VERSION "1.0"

NS_ :

BS_:

BU_: EngineECU ADAS_ECU BodyControl BatteryECU CrashSensor ACU LoadMonitor FaultInjector

BO_ 1 CRASH_Detected: 1 CrashSensor
 SG_ CrashFlag : 0|1@1+ (1,0) [0|1] "" Vector__XXX

BO_ 2 AIRBAG_Deploy: 1 ACU
 SG_ DeployCmd : 0|1@1+ (1,0) [0|1] "" Vector__XXX

BO_ 80 ACC_Data: 4 CrashSensor
 SG_ LongAccel : 0|16@1- (0.01,0) [-50|50] "m/s2" Vector__XXX
 SG_ LatAccel : 16|16@1- (0.01,0) [-50|50] "m/s2" Vector__XXX

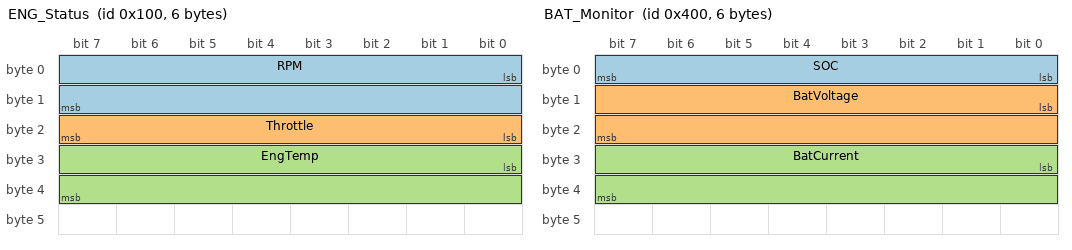
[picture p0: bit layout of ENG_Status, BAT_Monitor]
BO_ 256 ENG_Status: 6 EngineECU
 SG_ RPM : 0|16@1+ (0.25,0) [0|8000] "rpm" Vector__XXX
 SG_ Throttle : 16|8@1+ (0.5,0) [0|100] "%" Vector__XXX
 SG_ EngTemp : 24|16@1+ (0.1,-40) [-40|250] "degC" Vector__XXX

BO_ 257 ENG_Control: 3 EngineECU
 SG_ FuelInjPW : 0|16@1+ (0.01,0) [0|20] "ms" Vector__XXX
 SG_ IgnTiming : 16|8@1- (0.5,-20) [-20|40] "deg" Vector__XXX

BO_ 512 ADAS_Alert: 1 ADAS_ECU
 SG_ CollisionWarn : 0|4@1+ (1,0) [0|3] "" Vector__XXX
 SG_ LaneDeparture : 4|4@1+ (1,0) [0|3] "" Vector__XXX

BO_ 513 ADAS_Sensor: 4 ADAS_ECU
 SG_ FwdDistance : 0|16@1+ (0.1,0) [0|6553.5] "m" Vector__XXX
 SG_ VehSpeed : 16|16@1+ (0.01,0) [0|655.35] "km/h" Vector__XXX

BO_ 768 BCM_Status: 1 BodyControl
 SG_ DoorStatus : 0|4@1+ (1,0) [0|15] "" Vector__XXX
 SG_ LightStatus : 4|4@1+ (1,0) [0|15] "" Vector__XXX

BO_ 769 BCM_Climate: 2 BodyControl
 SG_ HVACTemp : 0|8@1- (0.5,-20) [-20|107.5] "degC" Vector__XXX
 SG_ FanSpeed : 8|8@1+ (1,0) [0|100] "%" Vector__XXX

BO_ 1024 BAT_Monitor: 6 BatteryECU
 SG_ SOC : 0|8@1+ (0.5,0) [0|100] "%" Vector__XXX
 SG_ BatVoltage : 8|16@1+ (0.01,0) [0|450] "V" Vector__XXX
 SG_ BatCurrent : 24|16@1- (0.1,0) [-1000|1000] "A" Vector__XXX

BO_ 1025 BAT_Thermal: 4 BatteryECU
 SG_ CellTemp : 0|16@1- (0.1,-40) [-40|80] "degC" Vector__XXX
 SG_ PackTemp : 16|16@1- (0.1,-40) [-40|80] "degC" Vector__XXX

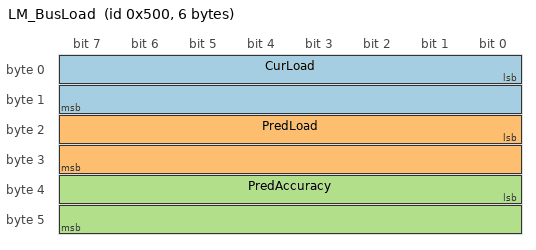
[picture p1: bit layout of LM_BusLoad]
BO_ 1280 LM_BusLoad: 6 LoadMonitor
 SG_ CurLoad : 0|16@1+ (0.1,0) [0|100] "%" Vector__XXX
 SG_ PredLoad : 16|16@1+ (0.1,0) [0|100] "%" Vector__XXX
 SG_ PredAccuracy : 32|16@1+ (0.1,0) [0|100] "%" Vector__XXX

CM_ BO_ 1 "Crash event broadcast from impact sensor to ACU.";
CM_ SG_ 1 CrashFlag "0=NoCrash, 1=CrashDetected";
CM_ BO_ 2 "Airbag deployment command from ACU.";
CM_ SG_ 2 DeployCmd "0=Standby, 1=Deploy";
CM_ BO_ 80 "Routine accelerometer data from crash sensor ECU.";
CM_ SG_ 80 LongAccel "Longitudinal acceleration. Spikes on crash event.";
CM_ SG_ 80 LatAccel "Lateral acceleration. Spikes on crash event.";
CM_ BO_ 256 "Engine status broadcast.";
CM_ SG_ 256 RPM "Engine speed in RPM.";
CM_ SG_ 256 Throttle "Throttle pedal position percentage.";
CM_ SG_ 256 EngTemp "Engine coolant temperature.";
CM_ BO_ 257 "Engine control parameters.";
CM_ SG_ 257 FuelInjPW "Fuel injector pulse width.";
CM_ SG_ 257 IgnTiming "Ignition timing advance.";
CM_ BO_ 512 "ADAS warning alerts.";
CM_ SG_ 512 CollisionWarn "0=NoWarn, 1=Advisory, 2=Warning, 3=Critical";
CM_ SG_ 512 LaneDeparture "0=Centered, 1=DriftLeft, 2=DriftRight, 3=Departure";
CM_ BO_ 513 "ADAS sensor readings";
CM_ SG_ 513 FwdDistance "Forward distance to nearest object in metres.";
CM_ SG_ 513 VehSpeed "Vehicle speed from ADAS module.";
CM_ BO_ 768 "Body Control Module status";
CM_ SG_ 768 DoorStatus "Bitmask: bit0=FL, bit1=FR, bit2=RL, bit3=RR.";
CM_ SG_ 768 LightStatus "Bitmask: bit0=Headlight, bit1=TailLight, bit2=FogLight, bit3=Hazard.";
CM_ BO_ 769 "HVAC and fan control data";
CM_ SG_ 769 HVACTemp "HVAC target temperature setpoint.";
CM_ SG_ 769 FanSpeed "HVAC fan speed percentage.";
CM_ BO_ 1024 "Battery state monitoring";
CM_ SG_ 1024 SOC "Battery State of Charge percentage.";
CM_ SG_ 1024 BatVoltage "Battery pack voltage.";
CM_ SG_ 1024 BatCurrent "Battery current.";
CM_ BO_ 1025 "Battery thermal monitoring";
CM_ SG_ 1025 CellTemp "Battery cell temperature.";
CM_ SG_ 1025 PackTemp "Battery pack average temperature.";
CM_ BO_ 1280 "Bus load monitoring broadcast";
CM_ SG_ 1280 CurLoad "Actual measured bus load this 100ms window.";
CM_ SG_ 1280 PredLoad "EWMA predicted bus load for next 100ms window.";
CM_ SG_ 1280 PredAccuracy "Prediction accuracy = 100 - |PredLoad - CurLoad|.";
BA_DEF_  "BusType" STRING ;
BA_DEF_ BO_  "GenMsgSendType" ENUM  "Cyclic","not_used","not_used","not_used","not_used","not_used","not_used","not_used","Event";
BA_DEF_ SG_  "GenSigStartValue" INT 0 999999;
BA_DEF_DEF_  "BusType" "CAN";
BA_DEF_DEF_  "GenMsgSendType" "Cyclic";
BA_DEF_DEF_  "GenSigStartValue" 0;
BA_ "GenMsgSendType" BO_ 1 8;
BA_ "GenMsgSendType" BO_ 2 8;
BA_ "GenMsgSendType" BO_ 512 8;
BA_ "GenSigStartValue" SG_ 256 RPM 3200;
BA_ "GenSigStartValue" SG_ 256 EngTemp 800;
BA_ "GenSigStartValue" SG_ 257 FuelInjPW 350;
BA_ "GenSigStartValue" SG_ 257 IgnTiming 60;
BA_ "GenSigStartValue" SG_ 513 FwdDistance 1000;
BA_ "GenSigStartValue" SG_ 513 VehSpeed 5000;
BA_ "GenSigStartValue" SG_ 769 HVACTemp 70;
BA_ "GenSigStartValue" SG_ 769 FanSpeed 30;
BA_ "GenSigStartValue" SG_ 1024 SOC 160;
BA_ "GenSigStartValue" SG_ 1024 BatVoltage 37000;
BA_ "GenSigStartValue" SG_ 1025 CellTemp 650;
BA_ "GenSigStartValue" SG_ 1025 PackTemp 650;
